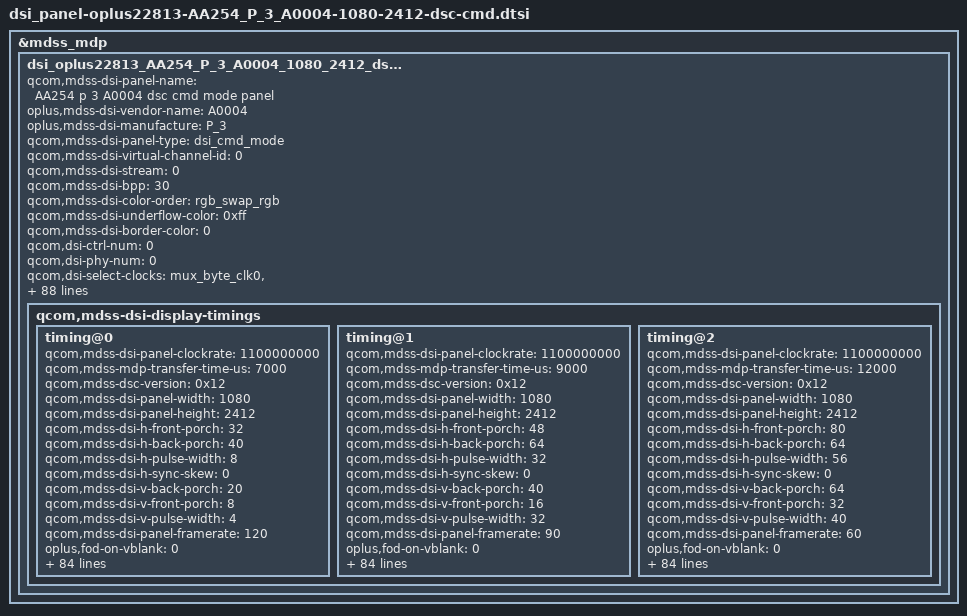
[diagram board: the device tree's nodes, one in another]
&mdss_mdp {
	dsi_oplus22813_AA254_P_3_A0004_1080_2412_dsc_cmd: qcom,mdss_dsi_oplus22813_AA254_P_3_A0004_1080_2412_dsc_cmd {
		qcom,mdss-dsi-panel-name = "AA254 p 3 A0004 dsc cmd mode panel";
		oplus,mdss-dsi-vendor-name = "A0004";
		oplus,mdss-dsi-manufacture = "P_3";
		qcom,mdss-dsi-panel-type = "dsi_cmd_mode";
		qcom,mdss-dsi-virtual-channel-id = <0>;
		qcom,mdss-dsi-stream = <0>;
		qcom,mdss-dsi-bpp = <30>;
		qcom,mdss-dsi-color-order = "rgb_swap_rgb";
		qcom,mdss-dsi-underflow-color = <0xff>;
		qcom,mdss-dsi-border-color = <0>;
		qcom,dsi-ctrl-num = <0>;
		qcom,dsi-phy-num = <0>;
		qcom,dsi-select-clocks = "src_byte_clk0", "src_pixel_clk0";

		qcom,mdss-dsi-traffic-mode = "non_burst_sync_event";
		qcom,mdss-dsi-lane-map = "lane_map_0123";
		qcom,mdss-dsi-bllp-eof-power-mode;
		qcom,mdss-dsi-bllp-power-mode;
		qcom,mdss-dsi-lane-0-state;
		qcom,mdss-dsi-lane-1-state;
		qcom,mdss-dsi-lane-2-state;
		qcom,mdss-dsi-lane-3-state;
		qcom,mdss-dsi-dma-trigger = "trigger_sw";
		qcom,mdss-dsi-mdp-trigger = "none";
		qcom,mdss-dsi-reset-sequence = <1 10>, <0 10>, <1 10>;
		qcom,mdss-dsi-te-pin-select = <1>;
		qcom,mdss-dsi-te-dcs-command = <1>;
		qcom,mdss-dsi-te-check-enable;
		qcom,mdss-dsi-te-using-te-pin;
		qcom,mdss-dsi-wr-mem-start = <0x2c>;
		qcom,mdss-dsi-wr-mem-continue = <0x3c>;
		qcom,mdss-dsi-panel-hdr-enabled;
		qcom,mdss-dsi-panel-hdr-color-primaries = <15000 15500 34000
			16000 13250 34500 7500 3000>;
		qcom,mdss-dsi-panel-peak-brightness = <4300000>;
		qcom,mdss-dsi-panel-blackness-level = <1023>;
		qcom,mdss-pan-physical-width-dimension = <70>;
		qcom,mdss-pan-physical-height-dimension = <155>;
		qcom,bl-update-flag = "delay_until_first_frame";
		qcom,mdss-dsi-lp11-init;
		//qcom,esd-check-enabled;
		qcom,mdss-dsi-panel-status-check-mode = "reg_read";
		qcom,mdss-dsi-panel-status-command = [06 01 00 01 05 00 02 0A 00];
		qcom,mdss-dsi-panel-status-command-state = "dsi_lp_mode";
		qcom,mdss-dsi-panel-status-value = <0x9C>;
		qcom,mdss-dsi-panel-status-read-length = <1>;

		qcom,mdss-dsi-display-timings {
			timing@0{
				qcom,mdss-dsi-panel-clockrate = <1100000000>;
				qcom,mdss-mdp-transfer-time-us = <7000>;
				qcom,mdss-dsc-version = <0x12>;
				qcom,mdss-dsi-panel-width = <1080>;
				qcom,mdss-dsi-panel-height = <2412>;
				qcom,mdss-dsi-h-front-porch = <32>;
				qcom,mdss-dsi-h-back-porch = <40>;
				qcom,mdss-dsi-h-pulse-width = <8>;
				qcom,mdss-dsi-h-sync-skew = <0>;
				qcom,mdss-dsi-v-back-porch = <20>;
				qcom,mdss-dsi-v-front-porch = <8>;
				qcom,mdss-dsi-v-pulse-width = <4>;
				qcom,mdss-dsi-panel-framerate = <120>;
				oplus,fod-on-vblank = <0>;
				oplus,fod-off-vblank = <0>;
				/* Apollo vsync config, need to measure TE signal */
				oplus,apollo-panel-vsync-width = <5680>;
				oplus,apollo-panel-vsync-period = <16850>;

				qcom,mdss-dsi-on-command = [
					//ini code for esd extend register
					39 01 00 00 00 00 04 FF 08 38 08
					39 01 00 00 00 00 02 C8 62
					39 01 00 00 00 00 04 FF 08 38 06
					39 01 00 00 00 00 02 C6 01
					39 01 00 00 00 00 04 FF 08 38 08
					39 01 00 00 00 00 02 D2 03
					39 01 00 00 00 00 04 FF 08 38 02
					39 01 00 00 00 00 02 F8 01
					39 01 00 00 00 00 04 FF 08 38 20
					39 01 00 00 00 00 02 B3 50
					39 01 00 00 00 00 02 B5 03
					//INI Setting
					39 01 00 00 00 00 04 FF 08 38 2D
					39 01 00 00 00 00 02 81 00

					//DSC Setting
					39 01 00 00 00 00 04 FF 08 38 07
					39 01 00 00 00 00 02 8A 01
					39 01 00 00 00 00 03 8B 11 E0
					39 01 00 00 00 00 64 81 00 00 00
						00 00 12 00 00 AB 30 A0 09 6C 04
						38 00 0C 02 1C 02 A3 01 9A 01 D8
						00 19 01 03 00 0A 00 0C 08 BB 0A
						5F 16 00 10 EC 07 10 20 00 06 0F
						0F 33 0E 1C 2A 38 46 54 62 69 70
						77 79 7B 7D 7E 01 C2 22 00 2A 40
						32 BE 3A FC 3A FA 3A F8 3B 38 3B
						78 3B 76 4B B6 4B B6 4B F4 5B F4
						7C 34 34 00 00 00 00 00

					//Demura IP/ON
					39 01 00 00 00 00 04 FF 08 38 21
					39 01 00 00 00 00 02 A4 18
					39 01 00 00 00 00 04 FF 08 38 19
					39 01 00 00 00 00 02 C5 00
					39 01 00 00 00 00 04 FF 08 38 30
					39 01 00 00 00 00 02 87 04
					39 01 00 00 00 00 02 AE 01
					39 01 00 00 00 00 02 80 01

					//Power OFF Sequence
					39 01 00 00 00 00 04 FF 08 38 08
					39 01 00 00 00 00 02 B0 55
					39 01 00 00 00 00 04 FF 08 38 1C
					39 01 00 00 00 00 03 FD 00 B2
					39 01 00 00 00 00 02 E2 CA
					39 01 00 00 00 00 03 FD 00 00
					39 01 00 00 00 00 04 FF 08 38 08
					39 01 00 00 00 00 02 B0 00

					39 01 00 00 00 00 04 FF 08 38 00
					39 01 00 00 00 00 02 35 00
					39 01 00 00 00 00 02 53 20
					39 01 00 00 00 00 05 51 0D BB 0F FE
					//Sleep out
					05 01 00 00 78 00 01 11
					05 01 00 00 1E 00 01 29

				];
				qcom,mdss-dsi-post-on-backlight = [
					/* Display On */
					39 00 00 00 00 00 04 FF 08 38 00
					05 01 00 00 78 00 01 11
					05 01 00 00 1E 00 01 29
				];
				qcom,mdss-dsi-timing-switch-command = [
					/* 120hz Transition */
					39 00 00 00 00 00 04 FF 08 38 2D
					39 00 00 00 00 00 02 81 00
					39 01 00 00 00 00 04 FF 08 38 00
				];
				qcom,mdss-dsi-off-command = [
					39 01 00 00 00 00 04 FF 08 38 00
					05 01 00 00 1A 00 01 28
					05 01 00 00 78 00 01 10
				];
				qcom,mdss-dsi-lp1-command = [
					/*	AOD Switch */
					39 00 00 00 00 00 04 FF 08 38 00
					39 00 00 00 00 00 05 51 00 00 0D BB
					/* AOD Mode ON */
					39 00 00 00 00 00 04 FF 08 38 05
					15 00 00 00 00 00 02 80 19
					39 00 00 00 00 00 0A FF AF 56 3D 2D 2D 2D 2D 2D FF
					39 00 00 00 00 00 04 FF 08 38 00
					05 01 00 00 22 00 01 39
				];
				qcom,mdss-dsi-nolp-command = [
					/* AOD Mode OFF */
					39 00 00 00 00 00 04 FF 08 38 00
					05 01 00 00 22 00 01 38
				];
				qcom,mdss-dsi-aod-high-mode-command = [
					/* AOD High Mode, 50nit */
					39 00 00 00 00 00 04 FF 08 38 00
					39 01 00 00 00 00 05 51 00 00 0D BB
				];
				qcom,mdss-dsi-aod-low-mode-command = [
					/* AOD Low Mode 10nit */
					39 00 00 00 00 00 04 FF 08 38 00
					39 01 00 00 00 00 05 51 00 00 0A E0
				];
				qcom,mdss-dsi-aod-hbm-on-command = [
					/* AOD Mode OFF */
					39 00 00 00 00 00 04 FF 08 38 00
					39 01 00 00 00 00 01 38
					/*HBM ON */
					39 01 00 00 00 00 05 51 0F FF 00 00
				];
				qcom,mdss-dsi-hbm-on-command = [
					39 00 00 00 00 00 04 FF 08 38 00
					39 01 00 00 00 00 05 51 0F FF 00 00
				];
				qcom,mdss-dsi-hbm-off-command = [
					39 00 00 00 00 00 04 FF 08 38 00
					39 01 00 00 00 00 05 51 0D BB 00 00
				];
				qcom,mdss-dsi-aod-hbm-off-command = [
					/*HBM OFF */
					39 00 00 00 00 00 04 FF 08 38 00
					39 01 00 00 00 00 05 51 0D BB 00 00
					/* AOD Mode ON */
					39 00 00 00 00 00 05 51 00 00 0A E0
					39 01 00 00 00 00 01 39
				];
				qcom,mdss-dsi-seed-off-command = [
				];
				qcom,mdss-dsi-seed-0-command = [
				];
				qcom,mdss-dsi-seed-1-command = [
				];
				qcom,mdss-dsi-seed-2-command = [
				];
				qcom,mdss-dsi-hbm-enter-switch-command = [
				];
				qcom,mdss-dsi-hbm-exit-switch-command = [
				];
				qcom,mdss-dsi-panel-info-switch-page-command = [
					/*read panel info switch page 00*/
					39 01 00 00 00 00 04 FF 08 38 00
				];
				qcom,mdss-dsi-default-switch-page-command = [
					/*switch default page*/
					39 01 00 00 00 00 04 FF 08 38 00
				];
				qcom,mdss-dsi-esd-switch-page-command = [
					39 01 00 00 00 00 04 FF 08 38 20
				];
				qcom,mdss-dsi-aod-hbm-on-command-state = "dsi_lp_mode";
				qcom,mdss-dsi-aod-hbm-off-command-state = "dsi_lp_mode";
				qcom,mdss-dsi-hbm-on-command-state = "dsi_lp_mode";
				qcom,mdss-dsi-seed-off-command-state = "dsi_lp_mode";
				qcom,mdss-dsi-seed-0-command-state = "dsi_lp_mode";
				qcom,mdss-dsi-seed-1-command-state = "dsi_lp_mode";
				qcom,mdss-dsi-seed-2-command-state = "dsi_lp_mode";
				qcom,mdss-dsi-lp1-command-state = "dsi_lp_mode";
				qcom,mdss-dsi-aod-high-mode-command-state = "dsi_lp_mode";
				qcom,mdss-dsi-aod-low-mode-command-state = "dsi_lp_mode";
				qcom,mdss-dsi-nolp-command-state = "dsi_lp_mode";
				qcom,mdss-dsi-osc-clk-mode0-command-state = "dsi_lp_mode";
				qcom,mdss-dsi-osc-clk-mode1-command-state = "dsi_lp_mode";
				qcom,mdss-dsi-post-on-backlight-state = "dsi_lp_mode";
				qcom,mdss-dsi-timing-switch-command-state = "dsi_lp_mode";
				qcom,mdss-dsi-on-command-state = "dsi_lp_mode";
				qcom,mdss-dsi-off-command-state = "dsi_lp_mode";
				qcom,mdss-dsi-panel-info-switch-page-command-state = "dsi_lp_mode";
				qcom,mdss-dsi-default-switch-page-command-state = "dsi_lp_mode";
				qcom,compression-mode = "dsc";
				qcom,mdss-dsc-slice-height = <12>;
				qcom,mdss-dsc-slice-width = <540>;
				qcom,mdss-dsc-slice-per-pkt = <2>;
				qcom,mdss-dsc-bit-per-component = <10>;
				qcom,mdss-dsc-bit-per-pixel = <10>;
				qcom,mdss-dsc-block-prediction-enable;
			};
			timing@1{
				qcom,mdss-dsi-panel-clockrate = <1100000000>;
				qcom,mdss-mdp-transfer-time-us = <9000>;
				qcom,mdss-dsc-version = <0x12>;
				qcom,mdss-dsi-panel-width = <1080>;
				qcom,mdss-dsi-panel-height = <2412>;
				qcom,mdss-dsi-h-front-porch = <48>;
				qcom,mdss-dsi-h-back-porch = <64>;
				qcom,mdss-dsi-h-pulse-width = <32>;
				qcom,mdss-dsi-h-sync-skew = <0>;
				qcom,mdss-dsi-v-back-porch = <40>;
				qcom,mdss-dsi-v-front-porch = <16>;
				qcom,mdss-dsi-v-pulse-width = <32>;
				qcom,mdss-dsi-panel-framerate = <90>;
				oplus,fod-on-vblank = <0>;
				oplus,fod-off-vblank = <0>;
				/* Apollo vsync config, need to measure TE signal */
				oplus,apollo-panel-vsync-width = <5680>;
				oplus,apollo-panel-vsync-period = <16850>;

				qcom,mdss-dsi-on-command = [
					//ini code for esd extend register
					39 01 00 00 00 00 04 FF 08 38 08
					39 01 00 00 00 00 02 C8 62
					39 01 00 00 00 00 04 FF 08 38 06
					39 01 00 00 00 00 02 C6 01
					39 01 00 00 00 00 04 FF 08 38 08
					39 01 00 00 00 00 02 D2 03
					39 01 00 00 00 00 04 FF 08 38 02
					39 01 00 00 00 00 02 F8 01
					39 01 00 00 00 00 04 FF 08 38 20
					39 01 00 00 00 00 02 B3 50
					39 01 00 00 00 00 02 B5 03
					//INI Setting
					39 01 00 00 00 00 04 FF 08 38 2D
					39 01 00 00 00 00 02 81 04

					//DSC Setting
					39 01 00 00 00 00 04 FF 08 38 07
					39 01 00 00 00 00 02 8A 01
					39 01 00 00 00 00 03 8B 11 E0
					39 01 00 00 00 00 64 81 00 00 00
						00 00 12 00 00 AB 30 A0 09 6C 04
						38 00 0C 02 1C 02 A3 01 9A 01 D8
						00 19 01 03 00 0A 00 0C 08 BB 0A
						5F 16 00 10 EC 07 10 20 00 06 0F
						0F 33 0E 1C 2A 38 46 54 62 69 70
						77 79 7B 7D 7E 01 C2 22 00 2A 40
						32 BE 3A FC 3A FA 3A F8 3B 38 3B
						78 3B 76 4B B6 4B B6 4B F4 5B F4
						7C 34 34 00 00 00 00 00

					//Demura IP/ON
					39 01 00 00 00 00 04 FF 08 38 21
					39 01 00 00 00 00 02 A4 18
					39 01 00 00 00 00 04 FF 08 38 19
					39 01 00 00 00 00 02 C5 00
					39 01 00 00 00 00 04 FF 08 38 30
					39 01 00 00 00 00 02 87 04
					39 01 00 00 00 00 02 AE 01
					39 01 00 00 00 00 02 80 01

					//Power OFF Sequence
					39 01 00 00 00 00 04 FF 08 38 08
					39 01 00 00 00 00 02 B0 55
					39 01 00 00 00 00 04 FF 08 38 1C
					39 01 00 00 00 00 03 FD 00 B2
					39 01 00 00 00 00 02 E2 CA
					39 01 00 00 00 00 03 FD 00 00
					39 01 00 00 00 00 04 FF 08 38 08
					39 01 00 00 00 00 02 B0 00

					39 01 00 00 00 00 04 FF 08 38 00
					39 01 00 00 00 00 02 35 00
					39 01 00 00 00 00 02 53 20
					39 01 00 00 00 00 05 51 0D BB 0F FE
					//Sleep out
					05 01 00 00 78 00 01 11
					05 01 00 00 1E 00 01 29

				];
				qcom,mdss-dsi-post-on-backlight = [
					/* Display On */
					39 00 00 00 00 00 04 FF 08 38 00
					05 01 00 00 78 00 01 11
					05 01 00 00 1E 00 01 29
				];
				qcom,mdss-dsi-timing-switch-command = [
					/* 90hz Transition */
					39 00 00 00 00 00 04 FF 08 38 2D
					39 00 00 00 00 00 02 81 04
					39 01 00 00 00 00 04 FF 08 38 00
				];
				qcom,mdss-dsi-off-command = [
					39 01 00 00 00 00 04 FF 08 38 00
					05 01 00 00 1A 00 01 28
					05 01 00 00 78 00 01 10
				];
				qcom,mdss-dsi-lp1-command = [
					/*	AOD Switch */
					39 00 00 00 00 00 04 FF 08 38 00
					39 00 00 00 00 00 05 51 00 00 0D BB
					/* AOD Mode ON */
					39 00 00 00 00 00 04 FF 08 38 05
					15 00 00 00 00 00 02 80 19
					39 00 00 00 00 00 0A FF AF 56 3D 2D 2D 2D 2D 2D FF
					39 00 00 00 00 00 04 FF 08 38 00
					05 01 00 00 22 00 01 39
				];
				qcom,mdss-dsi-nolp-command = [
					/* AOD Mode OFF */
					39 00 00 00 00 00 04 FF 08 38 00
					05 01 00 00 22 00 01 38
				];
				qcom,mdss-dsi-aod-high-mode-command = [
					/* AOD High Mode, 50nit */
					39 00 00 00 00 00 04 FF 08 38 00
					39 01 00 00 00 00 05 51 00 00 0D BB
				];
				qcom,mdss-dsi-aod-low-mode-command = [
					/* AOD Low Mode 10nit */
					39 00 00 00 00 00 04 FF 08 38 00
					39 01 00 00 00 00 05 51 00 00 0A E0
				];
				qcom,mdss-dsi-aod-hbm-on-command = [
					/* AOD Mode OFF */
					39 00 00 00 00 00 04 FF 08 38 00
					39 01 00 00 00 00 01 38
					/*HBM ON */
					39 01 00 00 00 00 05 51 0F FF 00 00
				];
				qcom,mdss-dsi-hbm-on-command = [
					39 00 00 00 00 00 04 FF 08 38 00
					39 01 00 00 00 00 05 51 0F FF 00 00
				];
				qcom,mdss-dsi-hbm-off-command = [
					39 00 00 00 00 00 04 FF 08 38 00
					39 01 00 00 00 00 05 51 0D BB 00 00
				];
				qcom,mdss-dsi-aod-hbm-off-command = [
					/*HBM OFF */
					39 00 00 00 00 00 04 FF 08 38 00
					39 01 00 00 00 00 05 51 0D BB 00 00
					/* AOD Mode ON */
					39 00 00 00 00 00 05 51 00 00 0A E0
					39 01 00 00 00 00 01 39
				];
				qcom,mdss-dsi-seed-off-command = [
				];
				qcom,mdss-dsi-seed-0-command = [
				];
				qcom,mdss-dsi-seed-1-command = [
				];
				qcom,mdss-dsi-seed-2-command = [
				];
				qcom,mdss-dsi-hbm-enter-switch-command = [
				];
				qcom,mdss-dsi-hbm-exit-switch-command = [
				];
				qcom,mdss-dsi-panel-info-switch-page-command = [
					/*read panel info switch page 00*/
					39 01 00 00 00 00 04 FF 08 38 00
				];
				qcom,mdss-dsi-default-switch-page-command = [
					/*switch default page*/
					39 01 00 00 00 00 04 FF 08 38 00
				];
				qcom,mdss-dsi-esd-switch-page-command = [
					39 01 00 00 00 00 04 FF 08 38 20
				];
				qcom,mdss-dsi-aod-hbm-on-command-state = "dsi_lp_mode";
				qcom,mdss-dsi-aod-hbm-off-command-state = "dsi_lp_mode";
				qcom,mdss-dsi-hbm-on-command-state = "dsi_lp_mode";
				qcom,mdss-dsi-seed-off-command-state = "dsi_lp_mode";
				qcom,mdss-dsi-seed-0-command-state = "dsi_lp_mode";
				qcom,mdss-dsi-seed-1-command-state = "dsi_lp_mode";
				qcom,mdss-dsi-seed-2-command-state = "dsi_lp_mode";
				qcom,mdss-dsi-lp1-command-state = "dsi_lp_mode";
				qcom,mdss-dsi-aod-high-mode-command-state = "dsi_lp_mode";
				qcom,mdss-dsi-aod-low-mode-command-state = "dsi_lp_mode";
				qcom,mdss-dsi-nolp-command-state = "dsi_lp_mode";
				qcom,mdss-dsi-osc-clk-mode0-command-state = "dsi_lp_mode";
				qcom,mdss-dsi-osc-clk-mode1-command-state = "dsi_lp_mode";
				qcom,mdss-dsi-post-on-backlight-state = "dsi_lp_mode";
				qcom,mdss-dsi-timing-switch-command-state = "dsi_lp_mode";
				qcom,mdss-dsi-on-command-state = "dsi_lp_mode";
				qcom,mdss-dsi-off-command-state = "dsi_lp_mode";
				qcom,mdss-dsi-panel-info-switch-page-command-state = "dsi_lp_mode";
				qcom,mdss-dsi-default-switch-page-command-state = "dsi_lp_mode";
				qcom,compression-mode = "dsc";
				qcom,mdss-dsc-slice-height = <12>;
				qcom,mdss-dsc-slice-width = <540>;
				qcom,mdss-dsc-slice-per-pkt = <2>;
				qcom,mdss-dsc-bit-per-component = <10>;
				qcom,mdss-dsc-bit-per-pixel = <10>;
				qcom,mdss-dsc-block-prediction-enable;
			};
			timing@2{
				qcom,mdss-dsi-panel-clockrate = <1100000000>;
				qcom,mdss-mdp-transfer-time-us = <12000>;
				qcom,mdss-dsc-version = <0x12>;
				qcom,mdss-dsi-panel-width = <1080>;
				qcom,mdss-dsi-panel-height = <2412>;
				qcom,mdss-dsi-h-front-porch = <80>;
				qcom,mdss-dsi-h-back-porch = <64>;
				qcom,mdss-dsi-h-pulse-width = <56>;
				qcom,mdss-dsi-h-sync-skew = <0>;
				qcom,mdss-dsi-v-back-porch = <64>;
				qcom,mdss-dsi-v-front-porch = <32>;
				qcom,mdss-dsi-v-pulse-width = <40>;
				qcom,mdss-dsi-panel-framerate = <60>;
				oplus,fod-on-vblank = <0>;
				oplus,fod-off-vblank = <0>;
				/* Apollo vsync config, need to measure TE signal */
				oplus,apollo-panel-vsync-width = <5680>;
				oplus,apollo-panel-vsync-period = <16850>;

				qcom,mdss-dsi-on-command = [
					//ini code for esd extend register
					39 01 00 00 00 00 04 FF 08 38 08
					39 01 00 00 00 00 02 C8 62
					39 01 00 00 00 00 04 FF 08 38 06
					39 01 00 00 00 00 02 C6 01
					39 01 00 00 00 00 04 FF 08 38 08
					39 01 00 00 00 00 02 D2 03
					39 01 00 00 00 00 04 FF 08 38 02
					39 01 00 00 00 00 02 F8 01
					39 01 00 00 00 00 04 FF 08 38 20
					39 01 00 00 00 00 02 B3 50
					39 01 00 00 00 00 02 B5 03
					//INI Setting
					39 01 00 00 00 00 04 FF 08 38 2D
					39 01 00 00 00 00 02 81 05

					//DSC Setting
					39 01 00 00 00 00 04 FF 08 38 07
					39 01 00 00 00 00 02 8A 01
					39 01 00 00 00 00 03 8B 11 E0
					39 01 00 00 00 00 64 81 00 00 00
						00 00 12 00 00 AB 30 A0 09 6C 04
						38 00 0C 02 1C 02 A3 01 9A 01 D8
						00 19 01 03 00 0A 00 0C 08 BB 0A
						5F 16 00 10 EC 07 10 20 00 06 0F
						0F 33 0E 1C 2A 38 46 54 62 69 70
						77 79 7B 7D 7E 01 C2 22 00 2A 40
						32 BE 3A FC 3A FA 3A F8 3B 38 3B
						78 3B 76 4B B6 4B B6 4B F4 5B F4
						7C 34 34 00 00 00 00 00

					//Demura IP/ON
					39 01 00 00 00 00 04 FF 08 38 21
					39 01 00 00 00 00 02 A4 18
					39 01 00 00 00 00 04 FF 08 38 19
					39 01 00 00 00 00 02 C5 00
					39 01 00 00 00 00 04 FF 08 38 30
					39 01 00 00 00 00 02 87 04
					39 01 00 00 00 00 02 AE 01
					39 01 00 00 00 00 02 80 01

					//Power OFF Sequence
					39 01 00 00 00 00 04 FF 08 38 08
					39 01 00 00 00 00 02 B0 55
					39 01 00 00 00 00 04 FF 08 38 1C
					39 01 00 00 00 00 03 FD 00 B2
					39 01 00 00 00 00 02 E2 CA
					39 01 00 00 00 00 03 FD 00 00
					39 01 00 00 00 00 04 FF 08 38 08
					39 01 00 00 00 00 02 B0 00

					39 01 00 00 00 00 04 FF 08 38 00
					39 01 00 00 00 00 02 35 00
					39 01 00 00 00 00 02 53 20
					39 01 00 00 00 00 05 51 0D BB 0F FE
					//Sleep out
					05 01 00 00 78 00 01 11
					05 01 00 00 1E 00 01 29

				];
				qcom,mdss-dsi-post-on-backlight = [
					/* Display On */
					39 00 00 00 00 00 04 FF 08 38 00
					05 01 00 00 78 00 01 11
					05 01 00 00 1E 00 01 29
				];
				qcom,mdss-dsi-timing-switch-command = [
					/* 60hz Transition */
					39 00 00 00 00 00 04 FF 08 38 2D
					39 00 00 00 00 00 02 81 05
					39 01 00 00 00 00 04 FF 08 38 00
				];
				qcom,mdss-dsi-off-command = [
					39 01 00 00 00 00 04 FF 08 38 00
					05 01 00 00 1A 00 01 28
					05 01 00 00 78 00 01 10
				];
				qcom,mdss-dsi-lp1-command = [
					/*	AOD Switch */
					39 00 00 00 00 00 04 FF 08 38 00
					39 00 00 00 00 00 05 51 00 00 0D BB
					/* AOD Mode ON */
					39 00 00 00 00 00 04 FF 08 38 05
					15 00 00 00 00 00 02 80 19
					39 00 00 00 00 00 0A FF AF 56 3D 2D 2D 2D 2D 2D FF
					39 00 00 00 00 00 04 FF 08 38 00
					05 01 00 00 22 00 01 39
				];
				qcom,mdss-dsi-nolp-command = [
					/* AOD Mode OFF */
					39 00 00 00 00 00 04 FF 08 38 00
					05 01 00 00 22 00 01 38
				];
				qcom,mdss-dsi-aod-high-mode-command = [
					/* AOD High Mode, 50nit */
					39 00 00 00 00 00 04 FF 08 38 00
					39 01 00 00 00 00 05 51 00 00 0D BB
				];
				qcom,mdss-dsi-aod-low-mode-command = [
					/* AOD Low Mode 10nit */
					39 00 00 00 00 00 04 FF 08 38 00
					39 01 00 00 00 00 05 51 00 00 0A E0
				];
				qcom,mdss-dsi-aod-hbm-on-command = [
					/* AOD Mode OFF */
					39 00 00 00 00 00 04 FF 08 38 00
					39 01 00 00 00 00 01 38
					/*HBM ON */
					39 01 00 00 00 00 05 51 0F FF 00 00
				];
				qcom,mdss-dsi-hbm-on-command = [
					39 00 00 00 00 00 04 FF 08 38 00
					39 01 00 00 00 00 05 51 0F FF 00 00
				];
				qcom,mdss-dsi-hbm-off-command = [
					39 00 00 00 00 00 04 FF 08 38 00
					39 01 00 00 00 00 05 51 0D BB 00 00
				];
				qcom,mdss-dsi-aod-hbm-off-command = [
					/*HBM OFF */
					39 00 00 00 00 00 04 FF 08 38 00
					39 01 00 00 00 00 05 51 0D BB 00 00
					/* AOD Mode ON */
					39 00 00 00 00 00 05 51 00 00 0A E0
					39 01 00 00 00 00 01 39
				];
				qcom,mdss-dsi-seed-off-command = [
				];
				qcom,mdss-dsi-seed-0-command = [
				];
				qcom,mdss-dsi-seed-1-command = [
				];
				qcom,mdss-dsi-seed-2-command = [
				];
				qcom,mdss-dsi-hbm-enter-switch-command = [
				];
				qcom,mdss-dsi-hbm-exit-switch-command = [
				];
				qcom,mdss-dsi-panel-info-switch-page-command = [
					/*read panel info switch page 00*/
					39 01 00 00 00 00 04 FF 08 38 00
				];
				qcom,mdss-dsi-default-switch-page-command = [
					/*switch default page*/
					39 01 00 00 00 00 04 FF 08 38 00
				];
				qcom,mdss-dsi-esd-switch-page-command = [
					39 01 00 00 00 00 04 FF 08 38 20
				];
				qcom,mdss-dsi-aod-hbm-on-command-state = "dsi_lp_mode";
				qcom,mdss-dsi-aod-hbm-off-command-state = "dsi_lp_mode";
				qcom,mdss-dsi-hbm-on-command-state = "dsi_lp_mode";
				qcom,mdss-dsi-seed-off-command-state = "dsi_lp_mode";
				qcom,mdss-dsi-seed-0-command-state = "dsi_lp_mode";
				qcom,mdss-dsi-seed-1-command-state = "dsi_lp_mode";
				qcom,mdss-dsi-seed-2-command-state = "dsi_lp_mode";
				qcom,mdss-dsi-lp1-command-state = "dsi_lp_mode";
				qcom,mdss-dsi-aod-high-mode-command-state = "dsi_lp_mode";
				qcom,mdss-dsi-aod-low-mode-command-state = "dsi_lp_mode";
				qcom,mdss-dsi-nolp-command-state = "dsi_lp_mode";
				qcom,mdss-dsi-osc-clk-mode0-command-state = "dsi_lp_mode";
				qcom,mdss-dsi-osc-clk-mode1-command-state = "dsi_lp_mode";
				qcom,mdss-dsi-post-on-backlight-state = "dsi_lp_mode";
				qcom,mdss-dsi-timing-switch-command-state = "dsi_lp_mode";
				qcom,mdss-dsi-on-command-state = "dsi_lp_mode";
				qcom,mdss-dsi-off-command-state = "dsi_lp_mode";
				qcom,mdss-dsi-panel-info-switch-page-command-state = "dsi_lp_mode";
				qcom,mdss-dsi-default-switch-page-command-state = "dsi_lp_mode";
				qcom,compression-mode = "dsc";
				qcom,mdss-dsc-slice-height = <12>;
				qcom,mdss-dsc-slice-width = <540>;
				qcom,mdss-dsc-slice-per-pkt = <2>;
				qcom,mdss-dsc-bit-per-component = <10>;
				qcom,mdss-dsc-bit-per-pixel = <10>;
				qcom,mdss-dsc-block-prediction-enable;
			};
		};
	};
};

&dsi_oplus22813_AA254_P_3_A0004_1080_2412_dsc_cmd {
	qcom,panel-supply-entries = <&dsi_panel_pwr_supply_vout>;
	qcom,mdss-dsi-bl-pmic-control-type = "bl_ctrl_dcs";
	qcom,mdss-dsi-bl-min-level = <1>;
	qcom,mdss-dsi-bl-max-level = <4095>;
	qcom,mdss-brightness-max-level = <4095>;
	qcom,mdss-dsi-bl-normal-max-level = <3515>;
	qcom,mdss-brightness-normal-max-level = <3515>;
	qcom,mdss-brightness-default-level = <1843>;
	qcom,mdss-dsi-bl-hbm-min-level = <3327>;
	qcom,platform-te-gpio = <&tlmm 80 0>;
	qcom,platform-reset-gpio = <&tlmm 44 0>;
	oplus,dsi-fod-brightness = <0 0xff>,
			<2 0xee>,
			<4 0xee>,
			<6 0xee>,
			<8 0xec>,
			<10 0xec>,
			<22 0xec>,
			<40 0xec>,
			<65 0xec>,
			<107 0xec>,
			<139 0xeb>,
			<173 0xea>,
			<204 0xe9>,
			<237 0xe8>,
			<267 0xe7>,
			<304 0xe6>,
			<335 0xe5>,
			<365 0xe4>,
			<395 0xe3>,
			<424 0xe2>,
			<454 0xe1>,
			<482 0xe0>,
			<507 0xdf>,
			<536 0xde>,
			<554 0xdd>,
			<568 0xdc>,
			<587 0xdb>,
			<603 0xda>,
			<620 0xd9>,
			<640 0xd8>,
			<654 0xd7>,
			<670 0xd6>,
			<690 0xd5>,
			<708 0xd4>,
			<724 0xd3>,
			<746 0xd2>,
			<764 0xd1>,
			<781 0xd0>,
			<804 0xcf>,
			<824 0xce>,
			<842 0xcd>,
			<861 0xcc>,
			<881 0xcb>,
			<901 0xca>,
			<921 0xc9>,
			<942 0xc8>,
			<959 0xc7>,
			<977 0xc6>,
			<995 0xc5>,
			<1015 0xc4>,
			<1033 0xc3>,
			<1054 0xc2>,
			<1078 0xc1>,
			<1098 0xc0>,
			<1121 0xbf>,
			<1137 0xbe>,
			<1159 0xbd>,
			<1178 0xbc>,
			<1197 0xbb>,
			<1222 0xba>,
			<1241 0xb9>,
			<1260 0xb8>,
			<1281 0xb7>,
			<1307 0xb6>,
			<1325 0xb5>,
			<1345 0xb4>,
			<1351 0xb3>,
			<1379 0xb2>,
			<1402 0xb1>,
			<1607 0xa6>,
			<1792 0x9c>,
			<1995 0x91>,
			<2203 0x85>,
			<2405 0x7a>,
			<2600 0x6f>,
			<2800 0x63>,
			<3000 0x56>,
			<3200 0x49>,
			<3400 0x3d>,
			<3515 0x35>;
	oplus,esd-check-flag-enabled;
	qcom,esd-check-enabled;
	qcom,mdss-dsi-panel-status-check-mode = "reg_read";
	qcom,mdss-dsi-panel-status-command = [
		06 01 00 01 00 00 01 0A
	];
	qcom,mdss-dsi-panel-status-command-state = "dsi_lp_mode";
	qcom,mdss-dsi-panel-status-value = <0x9C>;
	qcom,mdss-dsi-panel-status-read-length = <1>;

	qcom,ulps-enabled;
	qcom,suspend-ulps-enabled;
	qcom,dsi-select-clocks = "mux_byte_clk0", "mux_pixel_clk0",
				"src_byte_clk0", "src_pixel_clk0",
				"shadow_byte_clk0", "shadow_pixel_clk0";
	oplus,dsi-serial-number-index= <0>;
	oplus,dsi-serial-number-switch-page;
	oplus,dsi-serial-number-multi-regs = [00 01 02 03 04 05 06];

	qcom,mdss-dsi-display-timings {
		timing@0{
			qcom,mdss-dsi-panel-phy-timings = [00 24 0A 0A 1A 19 09 0A 09 02 04 00 1E 0F];
			qcom,display-topology = <1 1 1>;
			qcom,default-topology-index = <0>;
		};
		timing@1{
			qcom,mdss-dsi-panel-phy-timings = [00 24 0A 0A 1A 19 09 0A 09 02 04 00 1E 0F];
			qcom,display-topology = <1 1 1>;
			qcom,default-topology-index = <0>;
		};
		timing@2{
			qcom,mdss-dsi-panel-phy-timings = [00 24 0A 0A 1A 19 09 0A 09 02 04 00 1E 0F];
			qcom,display-topology = <1 1 1>;
			qcom,default-topology-index = <0>;
		};
	};
};

&dsi_oplus22813_AA254_P_3_A0004_1080_2412_dsc_cmd {
	qcom,panel_voltage_vddi_name = "vddi";
	qcom,panel_voltage_vddi = <0 1650000 1800000 1950000>;
	qcom,panel_voltage_vddr_name = "vddr";
	qcom,panel_voltage_vddr = <1 1450000 1500000 1600000>;
};

&dsi_oplus22813_AA254_P_3_A0004_1080_2412_dsc_cmd {
	pxlw,soft-iris-enable;
	oplus,enhance_mipi_strength;
};
